# FM33FH0XX register map
File version: 1.0
CPU: SC000 r1p0, little endian, no MPU, no FPU, 3 interrupt priority bits
Registers are 32-bit, read-write, reset 0x0 unless marked. A register's access mark holds for its fields unless they carry their own. Offsets are from the block's base; [hi:lo] are bit positions; {n}, {i} and the like mark numbered series.

## CMU — CMU module information
Base 0x40002400
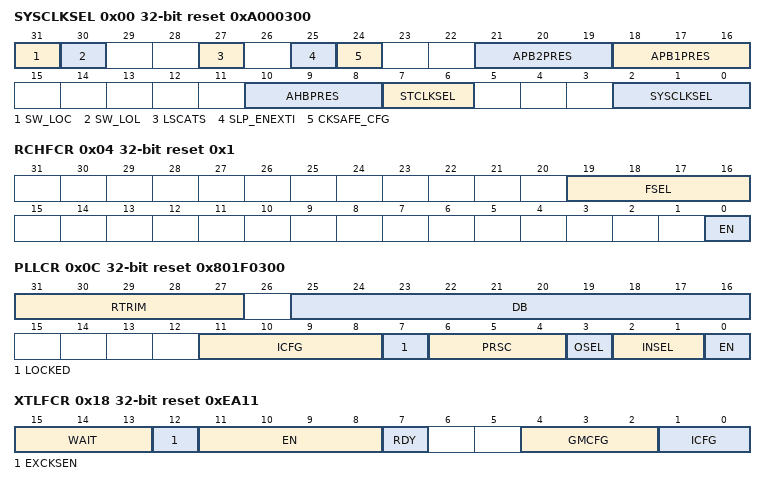
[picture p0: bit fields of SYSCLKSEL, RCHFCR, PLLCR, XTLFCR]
0x00 SYSCLKSEL reset 0xA000300
  [31] SW_LOC — SW_LOC field description
  [30] SW_LOL — SW_LOL field description
  [27] LSCATS — LSCATS field description
  [25] SLP_ENEXTI — SLP_ENEXTI field description
  [24] CKSAFE_CFG — CKSAFE_CFG field description
  [21:19] APB2PRES ro — APB2PRES field description
  [18:16] APB1PRES — APB1PRES field description
  [10:8] AHBPRES — AHBPRES field description
  [7:6] STCLKSEL — STCLKSEL field description
  [2:0] SYSCLKSEL — SYSCLKSEL field description
0x04 RCHFCR reset 0x1
  [19:16] FSEL — FSEL field description
  [0] EN — EN field description
0x08 RCHFTR reset 0x80
  [7:0] TRIM — TRIM field description
0x0C PLLCR reset 0x801F0300
  [31:27] RTRIM — RTRIM field description
  [25:16] DB — DB field description
  [11:8] ICFG — ICFG field description
  [7] LOCKED ro — LOCKED field description
  [6:4] PRSC — PRSC field description
  [3] OSEL — OSEL field description
  [2:1] INSEL — INSEL field description
  [0] EN — EN field description
0x10 RCLPCR
  [0] ENB ro — ENB field description
0x14 RCLPTR reset 0x80
  [7:0] TRIM — TRIM field description
0x18 XTLFCR reset 0xEA11
  [15:13] WAIT — WAIT field description
  [12] EXCKSEN — EXCKSEN field description
  [11:8] EN — EN field description
  [7] RDY ro — RDY field description
  [4:2] GMCFG — GMCFG field description
  [1:0] ICFG — ICFG field description
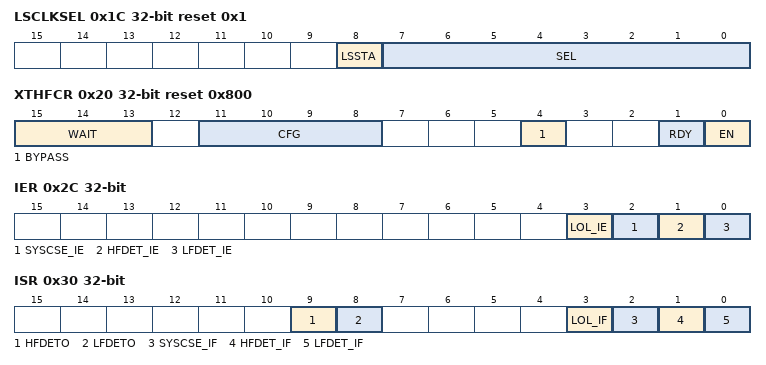
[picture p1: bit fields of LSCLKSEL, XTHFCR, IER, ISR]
0x1C LSCLKSEL reset 0x1
  [8] LSSTA — LSSTA field description
  [7:0] SEL — SEL field description
0x20 XTHFCR reset 0x800
  [15:13] WAIT — WAIT field description
  [11:8] CFG — CFG field description
  [4] BYPASS — BYPASS field description
  [1] RDY ro — RDY field description
  [0] EN — EN field description
0x2C IER
  [3] LOL_IE — LOL_IE field description
  [2] SYSCSE_IE — SYSCSE_IE field description
  [1] HFDET_IE — HFDET_IE field description
  [0] LFDET_IE — LFDET_IE field description
0x30 ISR
  [9] HFDETO ro — HFDETO field description
  [8] LFDETO ro — LFDETO field description
  [3] LOL_IF — LOL_IF field description
  [2] SYSCSE_IF — SYSCSE_IF field description
  [1] HFDET_IF — HFDET_IF field description
  [0] LFDET_IF — LFDET_IF field description
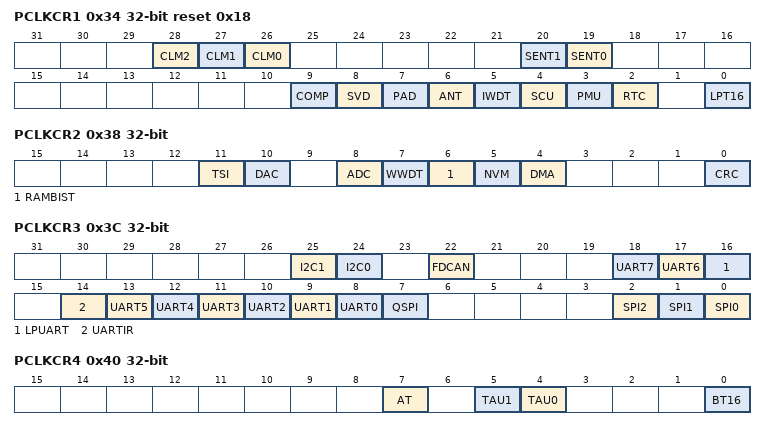
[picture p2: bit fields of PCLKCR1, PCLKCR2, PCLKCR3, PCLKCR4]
0x34 PCLKCR1 reset 0x18
  [28] CLM2 — CLM2 field description
  [27] CLM1 — CLM1 field description
  [26] CLM0 — CLM0 field description
  [20] SENT1 — SENT1 field description
  [19] SENT0 — SENT0 field description
  [9] COMP — COMP field description
  [8] SVD — SVD field description
  [7] PAD — PAD field description
  [6] ANT — ANT field description
  [5] IWDT — IWDT field description
  [4] SCU — SCU field description
  [3] PMU — PMU field description
  [2] RTC — RTC field description
  [0] LPT16 — LPT16 field description
0x38 PCLKCR2
  [11] TSI — TSI field description
  [10] DAC — DAC field description
  [8] ADC — ADC field description
  [7] WWDT — WWDT field description
  [6] RAMBIST — RAMBIST field description
  [5] NVM — NVM field description
  [4] DMA — DMA field description
  [0] CRC — CRC field description
0x3C PCLKCR3
  [25] I2C1 — I2C1 field description
  [24] I2C0 — I2C0 field description
  [22] FDCAN — FDCAN field description
  [18] UART7 — UART7 field description
  [17] UART6 — UART6 field description
  [16] LPUART — LPUART field description
  [14] UARTIR — UARTIR field description
  [n+8] UART{n} (n=0..5) — UART{n} field description
  [7] QSPI — QSPI field description
  [2] SPI2 — SPI2 field description
  [1] SPI1 — SPI1 field description
  [0] SPI0 — SPI0 field description
0x40 PCLKCR4
  [7] AT — AT field description
  [5] TAU1 — TAU1 field description
  [4] TAU0 — TAU0 field description
  [0] BT16 — BT16 field description
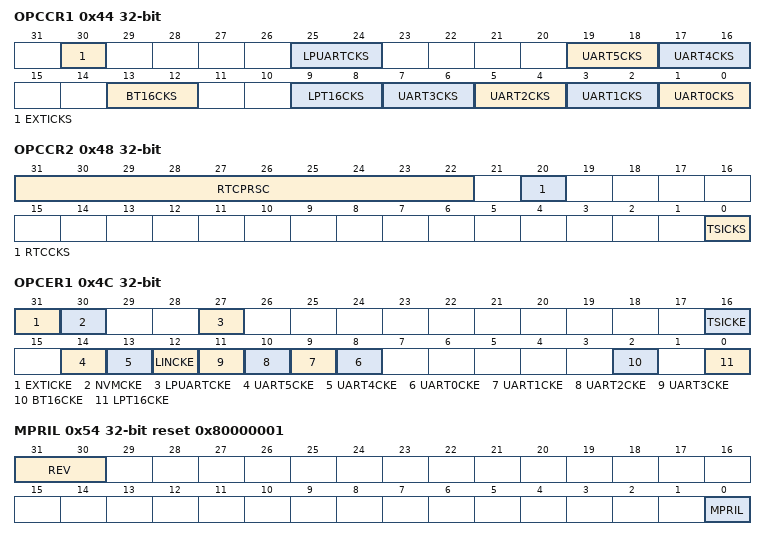
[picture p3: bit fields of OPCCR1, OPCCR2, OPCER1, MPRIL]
0x44 OPCCR1
  [30] EXTICKS — EXTICKS field description
  [25:24] LPUARTCKS — LPUARTCKS field description
  [19:18] UART5CKS — UART5CKS field description
  [17:16] UART4CKS — UART4CKS field description
  [13:12] BT16CKS — BT16CKS field description
  [9:8] LPT16CKS — LPT16CKS field description
  [2n+1:2n] UART{n}CKS (n=0..3) — UART{n}CKS field description
0x48 OPCCR2
  [31:22] RTCPRSC — RTCPRSC field description
  [20] RTCCKS — RTCCKS field description
  [0] TSICKS — TSICKS field description
0x4C OPCER1
  [31] EXTICKE — EXTICKE field description
  [30] NVMCKE — NVMCKE field description
  [27] LPUARTCKE — LPUARTCKE field description
  [16] TSICKE — TSICKE field description
  [14] UART5CKE — UART5CKE field description
  [13] UART4CKE — UART4CKE field description
  [12] LINCKE — LINCKE field description
  [n+8] UART{n}CKE (n=0..3) — UART{n}CKE field description
  [2] BT16CKE — BT16CKE field description
  [0] LPT16CKE — LPT16CKE field description
0x54 MPRIL reset 0x80000001
  [31:30] REV — REV field description
  [0] MPRIL — MPRIL field description
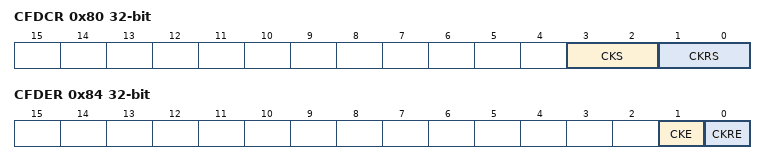
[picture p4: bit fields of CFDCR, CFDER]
0x80 CFDCR
  [3:2] CKS — CKS field description
  [1:0] CKRS — CKRS field description
0x84 CFDER
  [1] CKE — CKE field description
  [0] CKRE — CKRE field description
